# CY8C5267AXI_LP051 register map
File version: 0.1
Registers are 8-bit, read-write, no defined reset value unless marked. A register's access mark holds for its fields unless they carry their own. Offsets are from the block's base; [hi:lo] are bit positions; 'fields as' and 'values as' point back to an identical list.

## DataIn_Port15
Base 0x00000000
0x40006566 DataIn_Port15_STATUS_REG
0x40006586 DataIn_Port15_MASK_REG
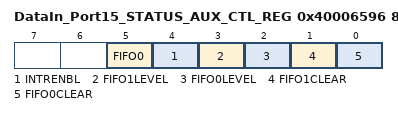
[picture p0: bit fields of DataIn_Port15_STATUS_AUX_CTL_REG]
0x40006596 DataIn_Port15_STATUS_AUX_CTL_REG
  [5] FIFO0 — FIFO0 clear
    1=ENABLED (Enable counter); 0=DISABLED (Disable counter)
  [4] INTRENBL — Enables or disables the Interrupt
    1=ENABLED (Interrupt enabled); 0=DISABLED (Interrupt disabled)
  [3] FIFO1LEVEL — FIFO level
    1=ENABLED (FIFO LVL: input mode: FIFO at least 1/2 empty; output mode: FIFO at least 1/2 full); 0=DISABLED (FIFO LVL: input mode: FIFO not full; output mode: FIFO not empty)
  [2] FIFO0LEVEL — FIFO level
    values as FIFO1LEVEL
  [1] FIFO1CLEAR — FIFO clear
    1=ENABLED (Clear FIFO state); 0=DISABLED (Normal FIFO operation)
  [0] FIFO0CLEAR — FIFO clear
    values as FIFO1CLEAR

## DataOut_Port15
Base 0x00000000
0x40006576 DataOut_Port15_CONTROL_REG

## DataIn_Port2
Base 0x00000000
0x40006569 DataIn_Port2_STATUS_REG
0x40006589 DataIn_Port2_MASK_REG
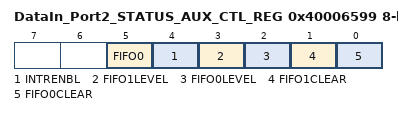
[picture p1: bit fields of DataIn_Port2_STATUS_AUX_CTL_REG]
0x40006599 DataIn_Port2_STATUS_AUX_CTL_REG
  [5] FIFO0 — FIFO0 clear
    1=ENABLED (Enable counter); 0=DISABLED (Disable counter)
  [4] INTRENBL — Enables or disables the Interrupt
    1=ENABLED (Interrupt enabled); 0=DISABLED (Interrupt disabled)
  [3] FIFO1LEVEL — FIFO level
    1=ENABLED (FIFO LVL: input mode: FIFO at least 1/2 empty; output mode: FIFO at least 1/2 full); 0=DISABLED (FIFO LVL: input mode: FIFO not full; output mode: FIFO not empty)
  [2] FIFO0LEVEL — FIFO level
    values as FIFO1LEVEL
  [1] FIFO1CLEAR — FIFO clear
    1=ENABLED (Clear FIFO state); 0=DISABLED (Normal FIFO operation)
  [0] FIFO0CLEAR — FIFO clear
    values as FIFO1CLEAR

## DataIn_Port3
Base 0x00000000
0x40006565 DataIn_Port3_STATUS_REG
0x40006585 DataIn_Port3_MASK_REG
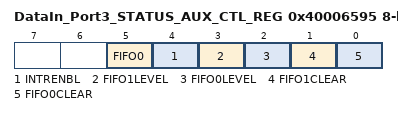
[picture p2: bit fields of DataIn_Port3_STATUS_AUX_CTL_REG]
0x40006595 DataIn_Port3_STATUS_AUX_CTL_REG
  [5] FIFO0 — FIFO0 clear
    1=ENABLED (Enable counter); 0=DISABLED (Disable counter)
  [4] INTRENBL — Enables or disables the Interrupt
    1=ENABLED (Interrupt enabled); 0=DISABLED (Interrupt disabled)
  [3] FIFO1LEVEL — FIFO level
    1=ENABLED (FIFO LVL: input mode: FIFO at least 1/2 empty; output mode: FIFO at least 1/2 full); 0=DISABLED (FIFO LVL: input mode: FIFO not full; output mode: FIFO not empty)
  [2] FIFO0LEVEL — FIFO level
    values as FIFO1LEVEL
  [1] FIFO1CLEAR — FIFO clear
    1=ENABLED (Clear FIFO state); 0=DISABLED (Normal FIFO operation)
  [0] FIFO0CLEAR — FIFO clear
    values as FIFO1CLEAR

## DataOut_Port0
Base 0x00000000
0x40006476 DataOut_Port0_CONTROL_REG

## Dir_Ctl
Base 0x00000000
0x40006574 Dir_Ctl_CONTROL_REG

## DataIn_Port0
Base 0x00000000
0x40006462 DataIn_Port0_STATUS_REG
0x40006482 DataIn_Port0_MASK_REG
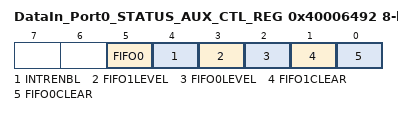
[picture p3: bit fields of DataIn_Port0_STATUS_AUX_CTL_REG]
0x40006492 DataIn_Port0_STATUS_AUX_CTL_REG
  [5] FIFO0 — FIFO0 clear
    1=ENABLED (Enable counter); 0=DISABLED (Disable counter)
  [4] INTRENBL — Enables or disables the Interrupt
    1=ENABLED (Interrupt enabled); 0=DISABLED (Interrupt disabled)
  [3] FIFO1LEVEL — FIFO level
    1=ENABLED (FIFO LVL: input mode: FIFO at least 1/2 empty; output mode: FIFO at least 1/2 full); 0=DISABLED (FIFO LVL: input mode: FIFO not full; output mode: FIFO not empty)
  [2] FIFO0LEVEL — FIFO level
    values as FIFO1LEVEL
  [1] FIFO1CLEAR — FIFO clear
    1=ENABLED (Clear FIFO state); 0=DISABLED (Normal FIFO operation)
  [0] FIFO0CLEAR — FIFO clear
    values as FIFO1CLEAR

## DataOut_Port3
Base 0x00000000
0x40006575 DataOut_Port3_CONTROL_REG

## DataIn_Port1
Base 0x00000000
0x40006568 DataIn_Port1_STATUS_REG
0x40006588 DataIn_Port1_MASK_REG
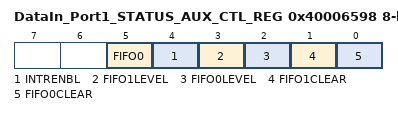
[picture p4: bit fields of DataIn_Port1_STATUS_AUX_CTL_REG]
0x40006598 DataIn_Port1_STATUS_AUX_CTL_REG
  [5] FIFO0 — FIFO0 clear
    1=ENABLED (Enable counter); 0=DISABLED (Disable counter)
  [4] INTRENBL — Enables or disables the Interrupt
    1=ENABLED (Interrupt enabled); 0=DISABLED (Interrupt disabled)
  [3] FIFO1LEVEL — FIFO level
    1=ENABLED (FIFO LVL: input mode: FIFO at least 1/2 empty; output mode: FIFO at least 1/2 full); 0=DISABLED (FIFO LVL: input mode: FIFO not full; output mode: FIFO not empty)
  [2] FIFO0LEVEL — FIFO level
    values as FIFO1LEVEL
  [1] FIFO1CLEAR — FIFO clear
    1=ENABLED (Clear FIFO state); 0=DISABLED (Normal FIFO operation)
  [0] FIFO0CLEAR — FIFO clear
    values as FIFO1CLEAR

## DataOut_Port4
Base 0x00000000
0x40006471 DataOut_Port4_CONTROL_REG

## DataIn_Port4
Base 0x00000000
0x40006461 DataIn_Port4_STATUS_REG
0x40006481 DataIn_Port4_MASK_REG
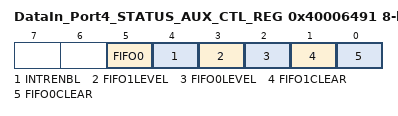
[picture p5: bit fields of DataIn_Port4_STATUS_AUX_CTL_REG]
0x40006491 DataIn_Port4_STATUS_AUX_CTL_REG
  [5] FIFO0 — FIFO0 clear
    1=ENABLED (Enable counter); 0=DISABLED (Disable counter)
  [4] INTRENBL — Enables or disables the Interrupt
    1=ENABLED (Interrupt enabled); 0=DISABLED (Interrupt disabled)
  [3] FIFO1LEVEL — FIFO level
    1=ENABLED (FIFO LVL: input mode: FIFO at least 1/2 empty; output mode: FIFO at least 1/2 full); 0=DISABLED (FIFO LVL: input mode: FIFO not full; output mode: FIFO not empty)
  [2] FIFO0LEVEL — FIFO level
    values as FIFO1LEVEL
  [1] FIFO1CLEAR — FIFO clear
    1=ENABLED (Clear FIFO state); 0=DISABLED (Normal FIFO operation)
  [0] FIFO0CLEAR — FIFO clear
    values as FIFO1CLEAR

## DataOut_Port2
Base 0x00000000
0x40006579 DataOut_Port2_CONTROL_REG
